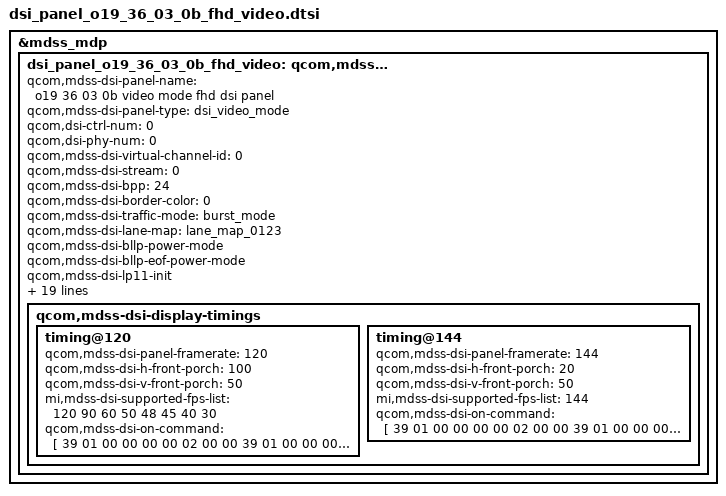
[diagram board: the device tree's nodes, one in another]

&mdss_mdp {
	dsi_panel_o19_36_03_0b_fhd_video: qcom,mdss_dsi_panel_o19_36_03_0b_fhd_video {
		qcom,mdss-dsi-panel-name =
			"o19 36 03 0b video mode fhd dsi panel";
		qcom,mdss-dsi-panel-type = "dsi_video_mode";
		qcom,dsi-ctrl-num = <0>;
		qcom,dsi-phy-num = <0>;
		qcom,mdss-dsi-virtual-channel-id = <0>;
		qcom,mdss-dsi-stream = <0>;
		qcom,mdss-dsi-bpp = <24>;
		qcom,mdss-dsi-border-color = <0>;
		qcom,mdss-dsi-traffic-mode = "burst_mode";
		qcom,mdss-dsi-lane-map = "lane_map_0123";
		qcom,mdss-dsi-bllp-power-mode;
		qcom,mdss-dsi-bllp-eof-power-mode;
		qcom,mdss-dsi-lp11-init;
		qcom,mdss-dsi-lane-0-state;
		qcom,mdss-dsi-lane-1-state;
		qcom,mdss-dsi-lane-2-state;
		qcom,mdss-dsi-lane-3-state;
		qcom,mdss-dsi-dma-trigger = "trigger_sw";
		qcom,mdss-dsi-mdp-trigger = "none";
		qcom,mdss-dsi-bl-lcd-number = <2>;
		qcom,mdss-dsi-reset-sequence = <1 10>, <0 10>, <1 10>;
		qcom,mdss-dsi-tx-eot-append;
		qcom,adjust-timer-wakeup-ms = <1>;
		qcom,mdss-brightness-init-level = <307>;
		qcom,mdss-pan-physical-width-dimension = <74>;
		qcom,mdss-pan-physical-height-dimension = <159>;
		qcom,mdss-dsi-pan-enable-dynamic-fps;
		qcom,mdss-dsi-pan-fps-update = "dfps_immediate_porch_mode_vfp";
		qcom,dsi-supported-dfps-list = <144 120 90 60 50 48 45 40 30>;
		mi,video-mode-multi-timing;
		qcom,mdss-dsi-display-timings {
			timing@120 {
				qcom,mdss-dsi-panel-framerate = <120>;
				qcom,mdss-dsi-h-front-porch = <100>;
				qcom,mdss-dsi-v-front-porch = <50>;
				mi,mdss-dsi-supported-fps-list = <120 90 60 50 48 45 40 30>;
				qcom,mdss-dsi-on-command = [
					39 01 00 00 00 00 02 00 00
					39 01 00 00 00 00 04 FF 87 25 01
					39 01 00 00 00 00 02 00 80
					39 01 00 00 00 00 03 FF 87 25

					39 01 00 00 00 00 02 00 80
					39 01 00 00 00 00 0D CA E1 D3 C3 B7 AD A4 9D 97 91 8C 88 84

					39 01 00 00 00 00 02 00 90
					39 01 00 00 00 00 0A CA FE FF 3C F5 FF 1E FA FF 8E

					39 01 00 00 00 00 02 00 82
					39 01 00 00 00 00 03 CE 2F 2F

					39 01 00 40 00 00 02 00 F6
					39 01 00 40 00 00 02 CF 78
					39 01 00 40 00 00 02 00 D2
					39 01 00 00 00 00 02 C0 01

					39 01 00 00 00 00 02 00 84
					39 01 00 00 00 00 02 B0 18

					39 01 00 00 00 00 02 00 A0
					39 01 00 00 00 00 04 CA 06 06 06

					39 01 00 00 00 00 02 00 B0
					39 01 00 00 00 00 04 CA 02 02 0C
					39 01 00 00 00 00 02 00 B5
					39 01 00 00 00 00 02 CA 04
					39 01 00 00 00 00 02 00 89
					39 01 00 00 00 00 02 CB 01

					39 01 00 00 00 00 03 51 00 00
					39 01 00 00 00 00 02 53 2C
					39 01 00 00 00 00 02 55 00
					39 01 00 00 00 00 02 35 00

					05 01 00 00 78 00 01 11
					05 01 00 00 05 00 01 29
				];

				#include "dsi_panel_o19_36_03_0b_fhd_video_common.dtsi"
			};
			timing@144 {
				qcom,mdss-dsi-panel-framerate = <144>;
				qcom,mdss-dsi-h-front-porch = <20>;
				qcom,mdss-dsi-v-front-porch = <50>;
				mi,mdss-dsi-supported-fps-list = <144>;

				qcom,mdss-dsi-on-command = [
					39 01 00 00 00 00 02 00 00
					39 01 00 00 00 00 04 FF 87 25 01
					39 01 00 00 00 00 02 00 80
					39 01 00 00 00 00 03 FF 87 25

					39 01 00 00 00 00 02 00 80
					39 01 00 00 00 00 0D CA E1 D3 C3 B7 AD A4 9D 97 91 8C 88 84

					39 01 00 00 00 00 02 00 90
					39 01 00 00 00 00 0A CA FE FF 3C F5 FF 1E FA FF 8E

					39 01 00 00 00 00 02 00 82
					39 01 00 00 00 00 03 CE 2F 2F

					39 01 00 40 00 00 02 00 F6
					39 01 00 40 00 00 02 CF 90
					39 01 00 40 00 00 02 00 D2
					39 01 00 00 00 00 02 C0 00

					39 01 00 00 00 00 02 00 84
					39 01 00 00 00 00 02 B0 18

					39 01 00 00 00 00 02 00 A0
					39 01 00 00 00 00 04 CA 06 06 06

					39 01 00 00 00 00 02 00 B0
					39 01 00 00 00 00 04 CA 02 02 0C
					39 01 00 00 00 00 02 00 B5
					39 01 00 00 00 00 02 CA 04
					39 01 00 00 00 00 02 00 89
					39 01 00 00 00 00 02 CB 01

					39 01 00 00 00 00 03 51 00 00
					39 01 00 00 00 00 02 53 2C
					39 01 00 00 00 00 02 55 00
					39 01 00 00 00 00 02 35 00

					05 01 00 00 78 00 01 11
					05 01 00 00 05 00 01 29
				];

				#include "dsi_panel_o19_36_03_0b_fhd_video_common.dtsi"
			};
		};
	};
};
